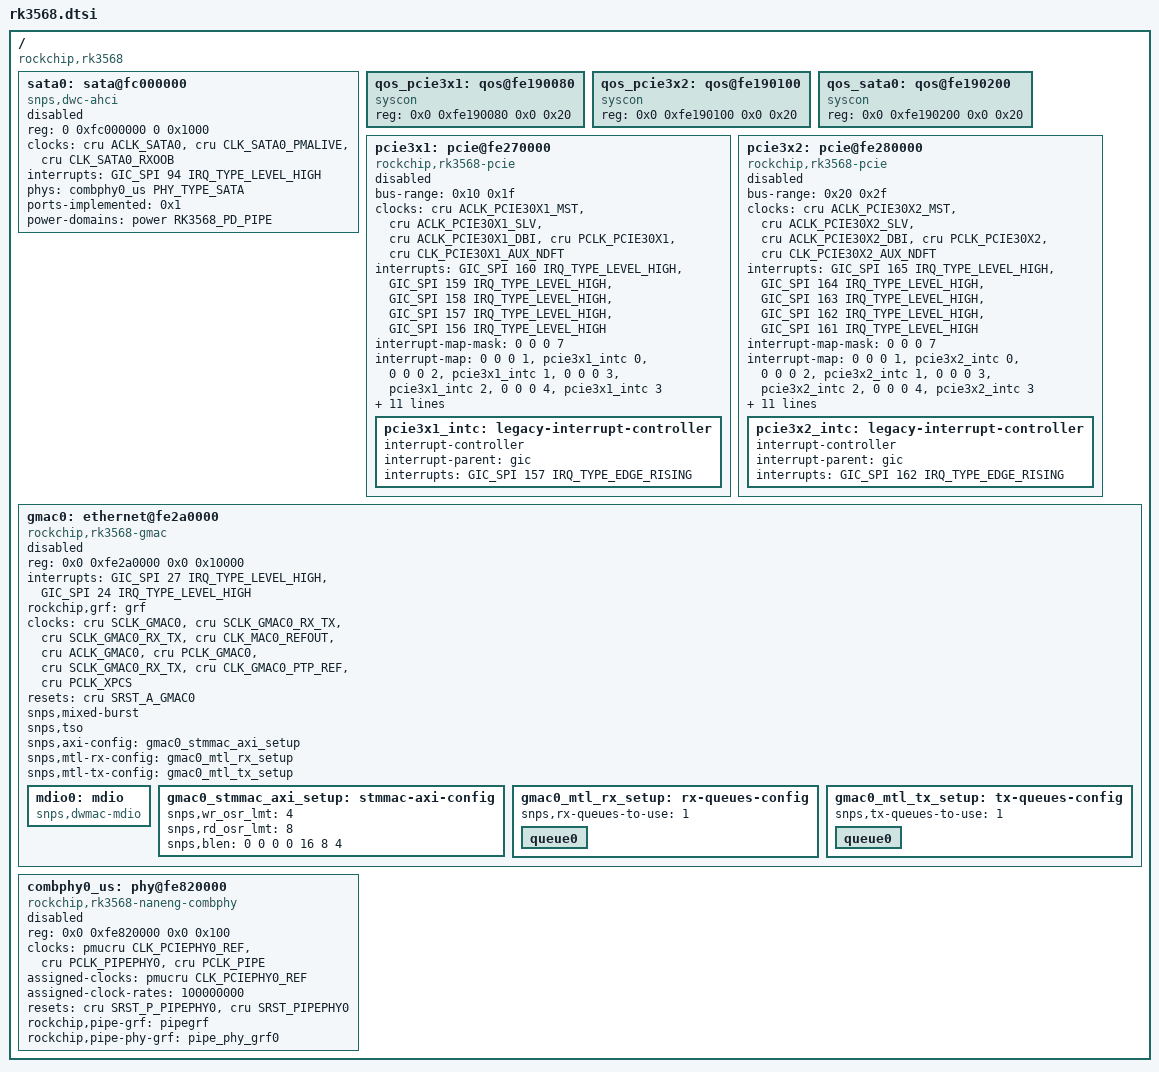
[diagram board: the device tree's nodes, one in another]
// SPDX-License-Identifier: (GPL-2.0+ OR MIT)
/*
 * Copyright (c) 2021 Rockchip Electronics Co., Ltd.
 */

#include "rk356x.dtsi"

/ {
	compatible = "rockchip,rk3568";

	sata0: sata@fc000000 {
		compatible = "snps,dwc-ahci";
		reg = <0 0xfc000000 0 0x1000>;
		clocks = <&cru ACLK_SATA0>, <&cru CLK_SATA0_PMALIVE>,
			 <&cru CLK_SATA0_RXOOB>;
		clock-names = "sata", "pmalive", "rxoob";
		interrupts = <GIC_SPI 94 IRQ_TYPE_LEVEL_HIGH>;
		interrupt-names = "hostc";
		phys = <&combphy0_us PHY_TYPE_SATA>;
		phy-names = "sata-phy";
		ports-implemented = <0x1>;
		power-domains = <&power RK3568_PD_PIPE>;
		status = "disabled";
	};

	qos_pcie3x1: qos@fe190080 {
		compatible = "syscon";
		reg = <0x0 0xfe190080 0x0 0x20>;
	};

	qos_pcie3x2: qos@fe190100 {
		compatible = "syscon";
		reg = <0x0 0xfe190100 0x0 0x20>;
	};

	qos_sata0: qos@fe190200 {
		compatible = "syscon";
		reg = <0x0 0xfe190200 0x0 0x20>;
	};

	pcie3x1: pcie@fe270000 {
		compatible = "rockchip,rk3568-pcie", "snps,dw-pcie";
		#address-cells = <3>;
		#size-cells = <2>;
		bus-range = <0x10 0x1f>;
		clocks = <&cru ACLK_PCIE30X1_MST>, <&cru ACLK_PCIE30X1_SLV>,
			 <&cru ACLK_PCIE30X1_DBI>, <&cru PCLK_PCIE30X1>,
			 <&cru CLK_PCIE30X1_AUX_NDFT>;
		clock-names = "aclk_mst", "aclk_slv",
			      "aclk_dbi", "pclk", "aux";
		device_type = "pci";
		interrupts = <GIC_SPI 160 IRQ_TYPE_LEVEL_HIGH>,
			     <GIC_SPI 159 IRQ_TYPE_LEVEL_HIGH>,
			     <GIC_SPI 158 IRQ_TYPE_LEVEL_HIGH>,
			     <GIC_SPI 157 IRQ_TYPE_LEVEL_HIGH>,
			     <GIC_SPI 156 IRQ_TYPE_LEVEL_HIGH>;
		interrupt-names = "sys", "pmc", "msg", "legacy", "err";
		#interrupt-cells = <1>;
		interrupt-map-mask = <0 0 0 7>;
		interrupt-map = <0 0 0 1 &pcie3x1_intc 0>,
				<0 0 0 2 &pcie3x1_intc 1>,
				<0 0 0 3 &pcie3x1_intc 2>,
				<0 0 0 4 &pcie3x1_intc 3>;
		linux,pci-domain = <1>;
		num-ib-windows = <6>;
		num-ob-windows = <2>;
		max-link-speed = <3>;
		msi-map = <0x1000 &its 0x1000 0x1000>;
		num-lanes = <1>;
		phys = <&pcie30phy>;
		phy-names = "pcie-phy";
		power-domains = <&power RK3568_PD_PIPE>;
		ranges = <0x00000800 0x0 0x40000000 0x3 0x40000000 0x0 0x800000
			  0x81000000 0x0 0x40800000 0x3 0x40800000 0x0 0x100000
			  0x83000000 0x0 0x40900000 0x3 0x40900000 0x0 0x3f700000>;
		reg = <0x3 0xc0400000 0x0 0x400000>,
		      <0x0 0xfe270000 0x0 0x10000>;
		reg-names = "pcie-dbi", "pcie-apb";
		resets = <&cru SRST_PCIE30X1_POWERUP>;
		reset-names = "pipe";
		/* rockchip,bifurcation; lane1 when using 1+1 */
		status = "disabled";

		pcie3x1_intc: legacy-interrupt-controller {
			interrupt-controller;
			#address-cells = <0>;
			#interrupt-cells = <1>;
			interrupt-parent = <&gic>;
			interrupts = <GIC_SPI 157 IRQ_TYPE_EDGE_RISING>;
		};
	};

	pcie3x2: pcie@fe280000 {
		compatible = "rockchip,rk3568-pcie", "snps,dw-pcie";
		#address-cells = <3>;
		#size-cells = <2>;
		bus-range = <0x20 0x2f>;
		clocks = <&cru ACLK_PCIE30X2_MST>, <&cru ACLK_PCIE30X2_SLV>,
			 <&cru ACLK_PCIE30X2_DBI>, <&cru PCLK_PCIE30X2>,
			 <&cru CLK_PCIE30X2_AUX_NDFT>;
		clock-names = "aclk_mst", "aclk_slv",
			      "aclk_dbi", "pclk", "aux";
		device_type = "pci";
		interrupts = <GIC_SPI 165 IRQ_TYPE_LEVEL_HIGH>,
			     <GIC_SPI 164 IRQ_TYPE_LEVEL_HIGH>,
			     <GIC_SPI 163 IRQ_TYPE_LEVEL_HIGH>,
			     <GIC_SPI 162 IRQ_TYPE_LEVEL_HIGH>,
			     <GIC_SPI 161 IRQ_TYPE_LEVEL_HIGH>;
		interrupt-names = "sys", "pmc", "msg", "legacy", "err";
		#interrupt-cells = <1>;
		interrupt-map-mask = <0 0 0 7>;
		interrupt-map = <0 0 0 1 &pcie3x2_intc 0>,
				<0 0 0 2 &pcie3x2_intc 1>,
				<0 0 0 3 &pcie3x2_intc 2>,
				<0 0 0 4 &pcie3x2_intc 3>;
		linux,pci-domain = <2>;
		num-ib-windows = <6>;
		num-ob-windows = <2>;
		max-link-speed = <3>;
		msi-map = <0x2000 &its 0x2000 0x1000>;
		num-lanes = <2>;
		phys = <&pcie30phy>;
		phy-names = "pcie-phy";
		power-domains = <&power RK3568_PD_PIPE>;
		ranges = <0x00000800 0x0 0x80000000 0x3 0x80000000 0x0 0x800000
			  0x81000000 0x0 0x80800000 0x3 0x80800000 0x0 0x100000
			  0x83000000 0x0 0x80900000 0x3 0x80900000 0x0 0x3f700000>;
		reg = <0x3 0xc0800000 0x0 0x400000>,
		      <0x0 0xfe280000 0x0 0x10000>;
		reg-names = "pcie-dbi", "pcie-apb";
		resets = <&cru SRST_PCIE30X2_POWERUP>;
		reset-names = "pipe";
		/* rockchip,bifurcation; lane0 when using 1+1 */
		status = "disabled";

		pcie3x2_intc: legacy-interrupt-controller {
			interrupt-controller;
			#address-cells = <0>;
			#interrupt-cells = <1>;
			interrupt-parent = <&gic>;
			interrupts = <GIC_SPI 162 IRQ_TYPE_EDGE_RISING>;
		};
	};

	gmac0: ethernet@fe2a0000 {
		compatible = "rockchip,rk3568-gmac", "snps,dwmac-4.20a";
		reg = <0x0 0xfe2a0000 0x0 0x10000>;
		interrupts = <GIC_SPI 27 IRQ_TYPE_LEVEL_HIGH>,
			     <GIC_SPI 24 IRQ_TYPE_LEVEL_HIGH>;
		interrupt-names = "macirq", "eth_wake_irq";
		rockchip,grf = <&grf>;
		clocks = <&cru SCLK_GMAC0>, <&cru SCLK_GMAC0_RX_TX>,
			 <&cru SCLK_GMAC0_RX_TX>, <&cru CLK_MAC0_REFOUT>,
			 <&cru ACLK_GMAC0>, <&cru PCLK_GMAC0>,
			 <&cru SCLK_GMAC0_RX_TX>, <&cru CLK_GMAC0_PTP_REF>,
			 <&cru PCLK_XPCS>;
		clock-names = "stmmaceth", "mac_clk_rx",
			      "mac_clk_tx", "clk_mac_refout",
			      "aclk_mac", "pclk_mac",
			      "clk_mac_speed", "ptp_ref",
			      "pclk_xpcs";
		resets = <&cru SRST_A_GMAC0>;
		reset-names = "stmmaceth";

		snps,mixed-burst;
		snps,tso;

		snps,axi-config = <&gmac0_stmmac_axi_setup>;
		snps,mtl-rx-config = <&gmac0_mtl_rx_setup>;
		snps,mtl-tx-config = <&gmac0_mtl_tx_setup>;
		status = "disabled";

		mdio0: mdio {
			compatible = "snps,dwmac-mdio";
			#address-cells = <0x1>;
			#size-cells = <0x0>;
		};

		gmac0_stmmac_axi_setup: stmmac-axi-config {
			snps,wr_osr_lmt = <4>;
			snps,rd_osr_lmt = <8>;
			snps,blen = <0 0 0 0 16 8 4>;
		};

		gmac0_mtl_rx_setup: rx-queues-config {
			snps,rx-queues-to-use = <1>;
			queue0 {};
		};

		gmac0_mtl_tx_setup: tx-queues-config {
			snps,tx-queues-to-use = <1>;
			queue0 {};
		};
	};

	combphy0_us: phy@fe820000 {
		compatible = "rockchip,rk3568-naneng-combphy";
		reg = <0x0 0xfe820000 0x0 0x100>;
		#phy-cells = <1>;
		clocks = <&pmucru CLK_PCIEPHY0_REF>, <&cru PCLK_PIPEPHY0>,
			 <&cru PCLK_PIPE>;
		clock-names = "refclk", "apbclk", "pipe_clk";
		assigned-clocks = <&pmucru CLK_PCIEPHY0_REF>;
		assigned-clock-rates = <100000000>;
		resets = <&cru SRST_P_PIPEPHY0>, <&cru SRST_PIPEPHY0>;
		reset-names = "combphy-apb", "combphy";
		rockchip,pipe-grf = <&pipegrf>;
		rockchip,pipe-phy-grf = <&pipe_phy_grf0>;
		status = "disabled";
	};
};
